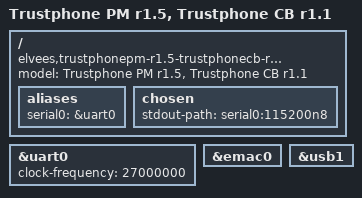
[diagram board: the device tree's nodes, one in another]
// SPDX-License-Identifier: GPL-2.0+
/*
 * Copyright 2021 RnD Center "ELVEES", JSC
 */

/dts-v1/;

#include "mcom03-trustphonepm-r1.5.dtsi"

/ {
	model = "Trustphone PM r1.5, Trustphone CB r1.1";
	compatible = "elvees,trustphonepm-r1.5-trustphonecb-r1.1",
		     "elvees,trustphonepm-trustphonecb",
		     "elvees,trustphonecb-r1.1",
		     "elvees,trustphonecb",
		     "elvees,trustphonepm-r1.5",
		     "elvees,trustphonepm",
		     "elvees,mcom03";

	aliases {
		serial0 = &uart0;
	};

	chosen {
		stdout-path = "serial0:115200n8";
	};
};

&uart0 {
	status = "okay";
	clock-frequency = <27000000>;
};

&emac0 {
	status = "okay";
};

/* Connected to USB hub */
&usb1 {
	status = "okay";
};
